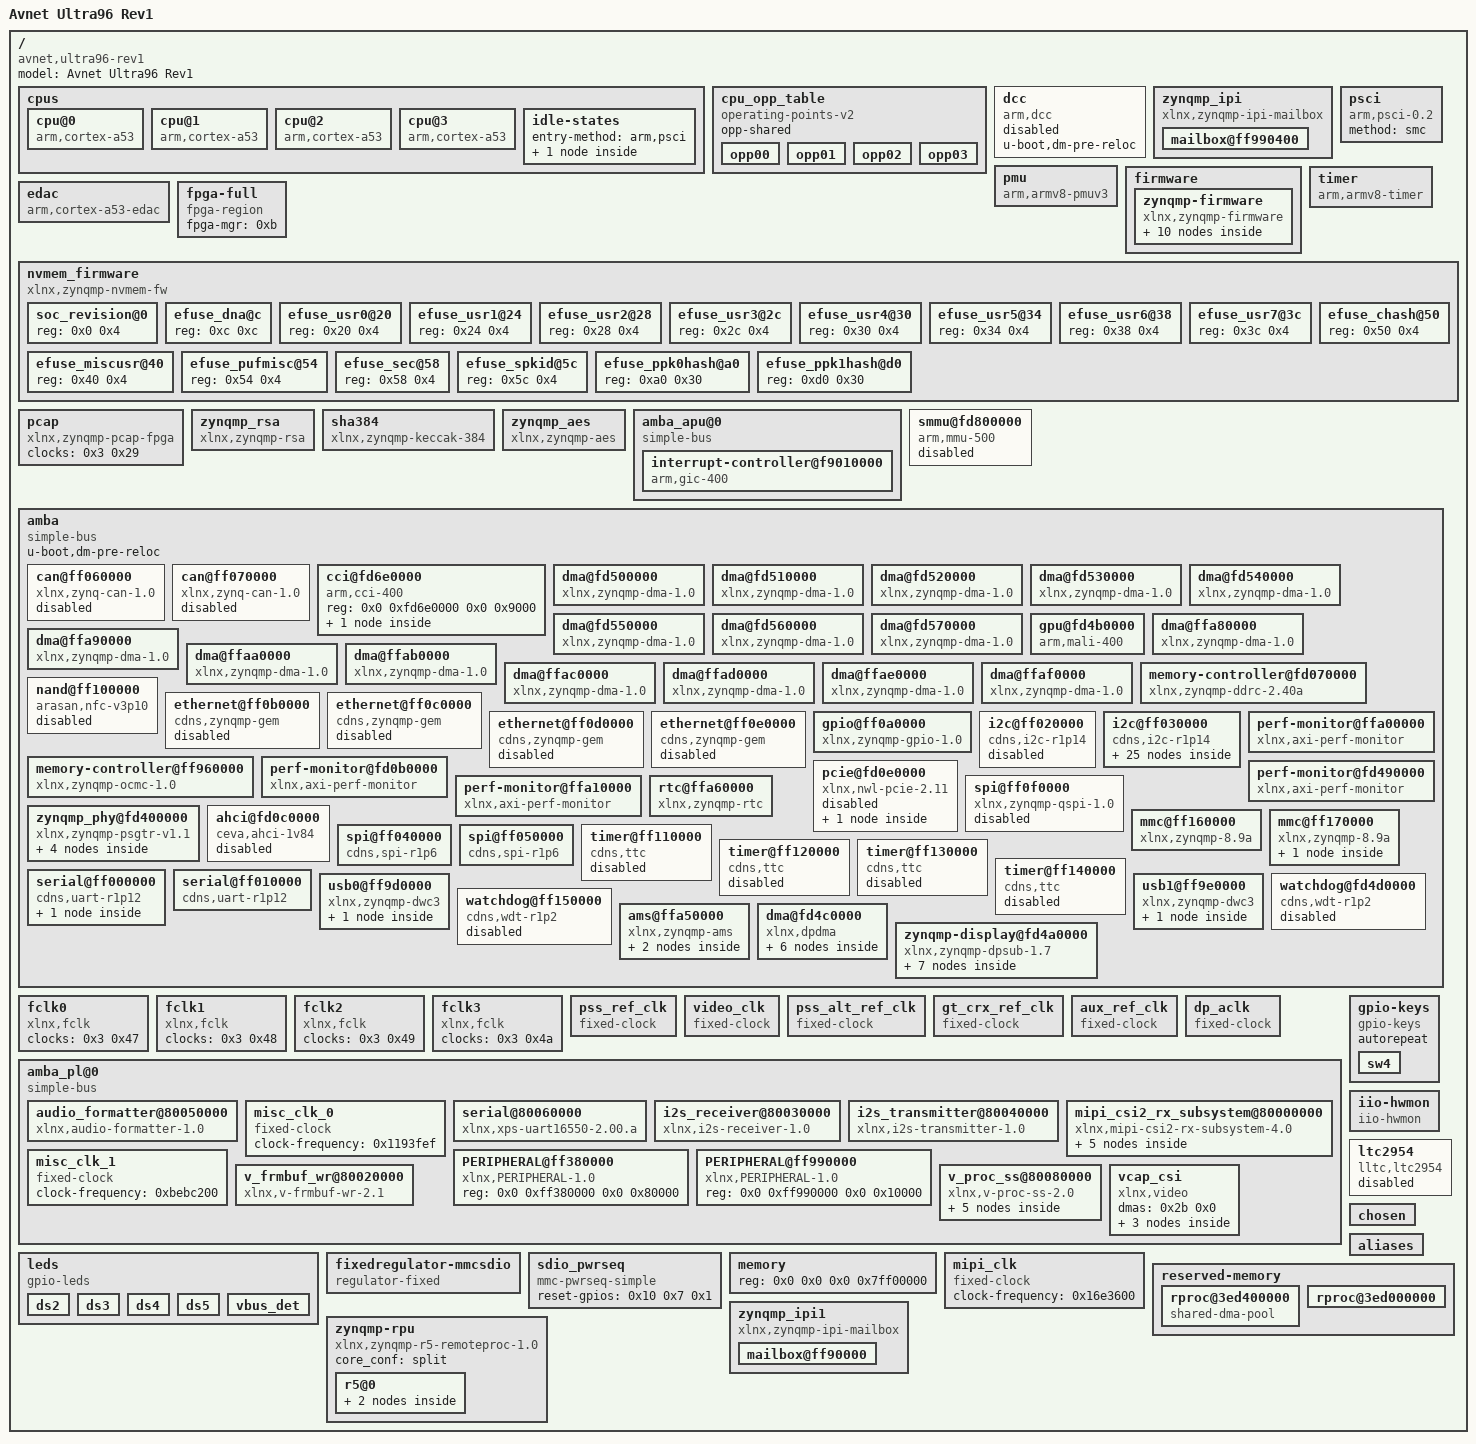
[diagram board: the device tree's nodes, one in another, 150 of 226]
/dts-v1/;

/ {
	compatible = "avnet,ultra96-rev1", "avnet,ultra96", "xlnx,zynqmp-zcu100-revC", "xlnx,zynqmp-zcu100", "xlnx,zynqmp";
	#address-cells = <0x2>;
	#size-cells = <0x2>;
	model = "Avnet Ultra96 Rev1";

	cpus {
		#address-cells = <0x1>;
		#size-cells = <0x0>;

		cpu@0 {
			compatible = "arm,cortex-a53", "arm,armv8";
			device_type = "cpu";
			enable-method = "psci";
			operating-points-v2 = <0x1>;
			reg = <0x0>;
			cpu-idle-states = <0x2>;
			clocks = <0x3 0xa>;
		};

		cpu@1 {
			compatible = "arm,cortex-a53", "arm,armv8";
			device_type = "cpu";
			enable-method = "psci";
			reg = <0x1>;
			operating-points-v2 = <0x1>;
			cpu-idle-states = <0x2>;
		};

		cpu@2 {
			compatible = "arm,cortex-a53", "arm,armv8";
			device_type = "cpu";
			enable-method = "psci";
			reg = <0x2>;
			operating-points-v2 = <0x1>;
			cpu-idle-states = <0x2>;
		};

		cpu@3 {
			compatible = "arm,cortex-a53", "arm,armv8";
			device_type = "cpu";
			enable-method = "psci";
			reg = <0x3>;
			operating-points-v2 = <0x1>;
			cpu-idle-states = <0x2>;
		};

		idle-states {
			entry-method = "arm,psci";

			cpu-sleep-0 {
				compatible = "arm,idle-state";
				arm,psci-suspend-param = <0x40000000>;
				local-timer-stop;
				entry-latency-us = <0x12c>;
				exit-latency-us = <0x258>;
				min-residency-us = <0x2710>;
				phandle = <0x2>;
			};
		};
	};

	cpu_opp_table {
		compatible = "operating-points-v2";
		opp-shared;
		phandle = <0x1>;

		opp00 {
			opp-hz = <0x0 0x47868bf4>;
			opp-microvolt = <0xf4240>;
			clock-latency-ns = <0x7a120>;
		};

		opp01 {
			opp-hz = <0x0 0x23c345fa>;
			opp-microvolt = <0xf4240>;
			clock-latency-ns = <0x7a120>;
		};

		opp02 {
			opp-hz = <0x0 0x17d783fc>;
			opp-microvolt = <0xf4240>;
			clock-latency-ns = <0x7a120>;
		};

		opp03 {
			opp-hz = <0x0 0x11e1a2fd>;
			opp-microvolt = <0xf4240>;
			clock-latency-ns = <0x7a120>;
		};
	};

	dcc {
		compatible = "arm,dcc";
		status = "disabled";
		u-boot,dm-pre-reloc;
	};

	zynqmp_ipi {
		compatible = "xlnx,zynqmp-ipi-mailbox";
		interrupt-parent = <0x4>;
		interrupts = <0x0 0x23 0x4>;
		xlnx,ipi-id = <0x0>;
		#address-cells = <0x2>;
		#size-cells = <0x2>;
		ranges;

		mailbox@ff990400 {
			reg = <0x0 0xff9905c0 0x0 0x20 0x0 0xff9905e0 0x0 0x20 0x0 0xff990e80 0x0 0x20 0x0 0xff990ea0 0x0 0x20>;
			reg-names = "local_request_region", "local_response_region", "remote_request_region", "remote_response_region";
			#mbox-cells = <0x1>;
			xlnx,ipi-id = <0x4>;
			phandle = <0x5>;
		};
	};

	pmu {
		compatible = "arm,armv8-pmuv3";
		interrupt-parent = <0x4>;
		interrupts = <0x0 0x8f 0x4 0x0 0x90 0x4 0x0 0x91 0x4 0x0 0x92 0x4>;
	};

	psci {
		compatible = "arm,psci-0.2";
		method = "smc";
	};

	firmware {

		zynqmp-firmware {
			compatible = "xlnx,zynqmp-firmware";
			u-boot,dm-pre-reloc;
			method = "smc";
			#power-domain-cells = <0x1>;
			phandle = <0xc>;

			zynqmp-power {
				compatible = "xlnx,zynqmp-power";
				interrupt-parent = <0x4>;
				interrupts = <0x0 0x23 0x4>;
				mboxes = <0x5 0x0 0x5 0x1>;
				mbox-names = "tx", "rx";
			};

			reset-controller {
				compatible = "xlnx,zynqmp-reset";
				#reset-cells = <0x1>;
				phandle = <0x16>;
			};

			pinctrl {
				compatible = "xlnx,zynqmp-pinctrl";
				status = "okay";

				i2c1-default {
					phandle = <0xe>;

					mux {
						groups = "i2c1_1_grp";
						function = "i2c1";
					};

					conf {
						groups = "i2c1_1_grp";
						bias-pull-up;
						slew-rate = <0x1>;
						io-standard = <0x1>;
					};
				};

				i2c1-gpio {
					phandle = <0xf>;

					mux {
						groups = "gpio0_4_grp", "gpio0_5_grp";
						function = "gpio0";
					};

					conf {
						groups = "gpio0_4_grp", "gpio0_5_grp";
						slew-rate = <0x1>;
						io-standard = <0x1>;
					};
				};
			};

			clock-controller {
				u-boot,dm-pre-reloc;
				#clock-cells = <0x1>;
				compatible = "xlnx,zynqmp-clk";
				clocks = <0x6 0x7 0x8 0x9 0xa>;
				clock-names = "pss_ref_clk", "video_clk", "pss_alt_ref_clk", "aux_ref_clk", "gt_crx_ref_clk";
				phandle = <0x3>;
			};
		};
	};

	timer {
		compatible = "arm,armv8-timer";
		interrupt-parent = <0x4>;
		interrupts = <0x1 0xd 0xf08 0x1 0xe 0xf08 0x1 0xb 0xf08 0x1 0xa 0xf08>;
	};

	edac {
		compatible = "arm,cortex-a53-edac";
	};

	fpga-full {
		compatible = "fpga-region";
		fpga-mgr = <0xb>;
		#address-cells = <0x2>;
		#size-cells = <0x2>;
	};

	nvmem_firmware {
		compatible = "xlnx,zynqmp-nvmem-fw";
		#address-cells = <0x1>;
		#size-cells = <0x1>;

		soc_revision@0 {
			reg = <0x0 0x4>;
			phandle = <0x15>;
		};

		efuse_dna@c {
			reg = <0xc 0xc>;
		};

		efuse_usr0@20 {
			reg = <0x20 0x4>;
		};

		efuse_usr1@24 {
			reg = <0x24 0x4>;
		};

		efuse_usr2@28 {
			reg = <0x28 0x4>;
		};

		efuse_usr3@2c {
			reg = <0x2c 0x4>;
		};

		efuse_usr4@30 {
			reg = <0x30 0x4>;
		};

		efuse_usr5@34 {
			reg = <0x34 0x4>;
		};

		efuse_usr6@38 {
			reg = <0x38 0x4>;
		};

		efuse_usr7@3c {
			reg = <0x3c 0x4>;
		};

		efuse_miscusr@40 {
			reg = <0x40 0x4>;
		};

		efuse_chash@50 {
			reg = <0x50 0x4>;
		};

		efuse_pufmisc@54 {
			reg = <0x54 0x4>;
		};

		efuse_sec@58 {
			reg = <0x58 0x4>;
		};

		efuse_spkid@5c {
			reg = <0x5c 0x4>;
		};

		efuse_ppk0hash@a0 {
			reg = <0xa0 0x30>;
		};

		efuse_ppk1hash@d0 {
			reg = <0xd0 0x30>;
		};
	};

	pcap {
		compatible = "xlnx,zynqmp-pcap-fpga";
		clock-names = "ref_clk";
		clocks = <0x3 0x29>;
		phandle = <0xb>;
	};

	zynqmp_rsa {
		compatible = "xlnx,zynqmp-rsa";
	};

	sha384 {
		compatible = "xlnx,zynqmp-keccak-384";
	};

	zynqmp_aes {
		compatible = "xlnx,zynqmp-aes";
	};

	amba_apu@0 {
		compatible = "simple-bus";
		#address-cells = <0x2>;
		#size-cells = <0x1>;
		ranges = <0x0 0x0 0x0 0x0 0xffffffff>;

		interrupt-controller@f9010000 {
			compatible = "arm,gic-400", "arm,cortex-a15-gic";
			#interrupt-cells = <0x3>;
			reg = <0x0 0xf9010000 0x10000 0x0 0xf9020000 0x20000 0x0 0xf9040000 0x20000 0x0 0xf9060000 0x20000>;
			interrupt-controller;
			interrupt-parent = <0x4>;
			interrupts = <0x1 0x9 0xf04>;
			num_cpus = <0x2>;
			num_interrupts = <0x60>;
			phandle = <0x4>;
		};
	};

	smmu@fd800000 {
		compatible = "arm,mmu-500";
		reg = <0x0 0xfd800000 0x0 0x20000>;
		#iommu-cells = <0x1>;
		status = "disabled";
		#global-interrupts = <0x1>;
		interrupt-parent = <0x4>;
		interrupts = <0x0 0x9b 0x4 0x0 0x9b 0x4 0x0 0x9b 0x4 0x0 0x9b 0x4 0x0 0x9b 0x4 0x0 0x9b 0x4 0x0 0x9b 0x4 0x0 0x9b 0x4 0x0 0x9b 0x4 0x0 0x9b 0x4 0x0 0x9b 0x4 0x0 0x9b 0x4 0x0 0x9b 0x4 0x0 0x9b 0x4 0x0 0x9b 0x4 0x0 0x9b 0x4 0x0 0x9b 0x4>;
		phandle = <0xd>;
	};

	amba {
		compatible = "simple-bus";
		u-boot,dm-pre-reloc;
		#address-cells = <0x2>;
		#size-cells = <0x2>;
		ranges;

		can@ff060000 {
			compatible = "xlnx,zynq-can-1.0";
			status = "disabled";
			clock-names = "can_clk", "pclk";
			reg = <0x0 0xff060000 0x0 0x1000>;
			interrupts = <0x0 0x17 0x4>;
			interrupt-parent = <0x4>;
			tx-fifo-depth = <0x40>;
			rx-fifo-depth = <0x40>;
			power-domains = <0xc 0x2f>;
			clocks = <0x3 0x3f 0x3 0x1f>;
		};

		can@ff070000 {
			compatible = "xlnx,zynq-can-1.0";
			status = "disabled";
			clock-names = "can_clk", "pclk";
			reg = <0x0 0xff070000 0x0 0x1000>;
			interrupts = <0x0 0x18 0x4>;
			interrupt-parent = <0x4>;
			tx-fifo-depth = <0x40>;
			rx-fifo-depth = <0x40>;
			power-domains = <0xc 0x30>;
			clocks = <0x3 0x40 0x3 0x1f>;
		};

		cci@fd6e0000 {
			compatible = "arm,cci-400";
			reg = <0x0 0xfd6e0000 0x0 0x9000>;
			ranges = <0x0 0x0 0xfd6e0000 0x10000>;
			#address-cells = <0x1>;
			#size-cells = <0x1>;

			pmu@9000 {
				compatible = "arm,cci-400-pmu,r1";
				reg = <0x9000 0x5000>;
				interrupt-parent = <0x4>;
				interrupts = <0x0 0x7b 0x4 0x0 0x7b 0x4 0x0 0x7b 0x4 0x0 0x7b 0x4 0x0 0x7b 0x4>;
			};
		};

		dma@fd500000 {
			status = "okay";
			compatible = "xlnx,zynqmp-dma-1.0";
			reg = <0x0 0xfd500000 0x0 0x1000>;
			interrupt-parent = <0x4>;
			interrupts = <0x0 0x7c 0x4>;
			clock-names = "clk_main", "clk_apb";
			xlnx,bus-width = <0x80>;
			#stream-id-cells = <0x1>;
			iommus = <0xd 0x14e8>;
			power-domains = <0xc 0x2a>;
			clocks = <0x3 0x13 0x3 0x1f>;
		};

		dma@fd510000 {
			status = "okay";
			compatible = "xlnx,zynqmp-dma-1.0";
			reg = <0x0 0xfd510000 0x0 0x1000>;
			interrupt-parent = <0x4>;
			interrupts = <0x0 0x7d 0x4>;
			clock-names = "clk_main", "clk_apb";
			xlnx,bus-width = <0x80>;
			#stream-id-cells = <0x1>;
			iommus = <0xd 0x14e9>;
			power-domains = <0xc 0x2a>;
			clocks = <0x3 0x13 0x3 0x1f>;
		};

		dma@fd520000 {
			status = "okay";
			compatible = "xlnx,zynqmp-dma-1.0";
			reg = <0x0 0xfd520000 0x0 0x1000>;
			interrupt-parent = <0x4>;
			interrupts = <0x0 0x7e 0x4>;
			clock-names = "clk_main", "clk_apb";
			xlnx,bus-width = <0x80>;
			#stream-id-cells = <0x1>;
			iommus = <0xd 0x14ea>;
			power-domains = <0xc 0x2a>;
			clocks = <0x3 0x13 0x3 0x1f>;
		};

		dma@fd530000 {
			status = "okay";
			compatible = "xlnx,zynqmp-dma-1.0";
			reg = <0x0 0xfd530000 0x0 0x1000>;
			interrupt-parent = <0x4>;
			interrupts = <0x0 0x7f 0x4>;
			clock-names = "clk_main", "clk_apb";
			xlnx,bus-width = <0x80>;
			#stream-id-cells = <0x1>;
			iommus = <0xd 0x14eb>;
			power-domains = <0xc 0x2a>;
			clocks = <0x3 0x13 0x3 0x1f>;
		};

		dma@fd540000 {
			status = "okay";
			compatible = "xlnx,zynqmp-dma-1.0";
			reg = <0x0 0xfd540000 0x0 0x1000>;
			interrupt-parent = <0x4>;
			interrupts = <0x0 0x80 0x4>;
			clock-names = "clk_main", "clk_apb";
			xlnx,bus-width = <0x80>;
			#stream-id-cells = <0x1>;
			iommus = <0xd 0x14ec>;
			power-domains = <0xc 0x2a>;
			clocks = <0x3 0x13 0x3 0x1f>;
		};

		dma@fd550000 {
			status = "okay";
			compatible = "xlnx,zynqmp-dma-1.0";
			reg = <0x0 0xfd550000 0x0 0x1000>;
			interrupt-parent = <0x4>;
			interrupts = <0x0 0x81 0x4>;
			clock-names = "clk_main", "clk_apb";
			xlnx,bus-width = <0x80>;
			#stream-id-cells = <0x1>;
			iommus = <0xd 0x14ed>;
			power-domains = <0xc 0x2a>;
			clocks = <0x3 0x13 0x3 0x1f>;
		};

		dma@fd560000 {
			status = "okay";
			compatible = "xlnx,zynqmp-dma-1.0";
			reg = <0x0 0xfd560000 0x0 0x1000>;
			interrupt-parent = <0x4>;
			interrupts = <0x0 0x82 0x4>;
			clock-names = "clk_main", "clk_apb";
			xlnx,bus-width = <0x80>;
			#stream-id-cells = <0x1>;
			iommus = <0xd 0x14ee>;
			power-domains = <0xc 0x2a>;
			clocks = <0x3 0x13 0x3 0x1f>;
		};

		dma@fd570000 {
			status = "okay";
			compatible = "xlnx,zynqmp-dma-1.0";
			reg = <0x0 0xfd570000 0x0 0x1000>;
			interrupt-parent = <0x4>;
			interrupts = <0x0 0x83 0x4>;
			clock-names = "clk_main", "clk_apb";
			xlnx,bus-width = <0x80>;
			#stream-id-cells = <0x1>;
			iommus = <0xd 0x14ef>;
			power-domains = <0xc 0x2a>;
			clocks = <0x3 0x13 0x3 0x1f>;
		};

		gpu@fd4b0000 {
			status = "okay";
			compatible = "arm,mali-400", "arm,mali-utgard";
			reg = <0x0 0xfd4b0000 0x0 0x10000>;
			interrupt-parent = <0x4>;
			interrupts = <0x0 0x84 0x4 0x0 0x84 0x4 0x0 0x84 0x4 0x0 0x84 0x4 0x0 0x84 0x4 0x0 0x84 0x4>;
			interrupt-names = "IRQGP", "IRQGPMMU", "IRQPP0", "IRQPPMMU0", "IRQPP1", "IRQPPMMU1";
			clock-names = "gpu", "gpu_pp0", "gpu_pp1";
			power-domains = <0xc 0x3a>;
			clocks = <0x3 0x18 0x3 0x19 0x3 0x1a>;
			xlnx,tz-nonsecure = <0x1>;
		};

		dma@ffa80000 {
			status = "okay";
			compatible = "xlnx,zynqmp-dma-1.0";
			reg = <0x0 0xffa80000 0x0 0x1000>;
			interrupt-parent = <0x4>;
			interrupts = <0x0 0x4d 0x4>;
			clock-names = "clk_main", "clk_apb";
			xlnx,bus-width = <0x40>;
			#stream-id-cells = <0x1>;
			power-domains = <0xc 0x2b>;
			clocks = <0x3 0x44 0x3 0x1f>;
		};

		dma@ffa90000 {
			status = "okay";
			compatible = "xlnx,zynqmp-dma-1.0";
			reg = <0x0 0xffa90000 0x0 0x1000>;
			interrupt-parent = <0x4>;
			interrupts = <0x0 0x4e 0x4>;
			clock-names = "clk_main", "clk_apb";
			xlnx,bus-width = <0x40>;
			#stream-id-cells = <0x1>;
			power-domains = <0xc 0x2b>;
			clocks = <0x3 0x44 0x3 0x1f>;
		};

		dma@ffaa0000 {
			status = "okay";
			compatible = "xlnx,zynqmp-dma-1.0";
			reg = <0x0 0xffaa0000 0x0 0x1000>;
			interrupt-parent = <0x4>;
			interrupts = <0x0 0x4f 0x4>;
			clock-names = "clk_main", "clk_apb";
			xlnx,bus-width = <0x40>;
			#stream-id-cells = <0x1>;
			power-domains = <0xc 0x2b>;
			clocks = <0x3 0x44 0x3 0x1f>;
		};

		dma@ffab0000 {
			status = "okay";
			compatible = "xlnx,zynqmp-dma-1.0";
			reg = <0x0 0xffab0000 0x0 0x1000>;
			interrupt-parent = <0x4>;
			interrupts = <0x0 0x50 0x4>;
			clock-names = "clk_main", "clk_apb";
			xlnx,bus-width = <0x40>;
			#stream-id-cells = <0x1>;
			power-domains = <0xc 0x2b>;
			clocks = <0x3 0x44 0x3 0x1f>;
		};

		dma@ffac0000 {
			status = "okay";
			compatible = "xlnx,zynqmp-dma-1.0";
			reg = <0x0 0xffac0000 0x0 0x1000>;
			interrupt-parent = <0x4>;
			interrupts = <0x0 0x51 0x4>;
			clock-names = "clk_main", "clk_apb";
			xlnx,bus-width = <0x40>;
			#stream-id-cells = <0x1>;
			power-domains = <0xc 0x2b>;
			clocks = <0x3 0x44 0x3 0x1f>;
		};

		dma@ffad0000 {
			status = "okay";
			compatible = "xlnx,zynqmp-dma-1.0";
			reg = <0x0 0xffad0000 0x0 0x1000>;
			interrupt-parent = <0x4>;
			interrupts = <0x0 0x52 0x4>;
			clock-names = "clk_main", "clk_apb";
			xlnx,bus-width = <0x40>;
			#stream-id-cells = <0x1>;
			power-domains = <0xc 0x2b>;
			clocks = <0x3 0x44 0x3 0x1f>;
		};

		dma@ffae0000 {
			status = "okay";
			compatible = "xlnx,zynqmp-dma-1.0";
			reg = <0x0 0xffae0000 0x0 0x1000>;
			interrupt-parent = <0x4>;
			interrupts = <0x0 0x53 0x4>;
			clock-names = "clk_main", "clk_apb";
			xlnx,bus-width = <0x40>;
			#stream-id-cells = <0x1>;
			power-domains = <0xc 0x2b>;
			clocks = <0x3 0x44 0x3 0x1f>;
		};

		dma@ffaf0000 {
			status = "okay";
			compatible = "xlnx,zynqmp-dma-1.0";
			reg = <0x0 0xffaf0000 0x0 0x1000>;
			interrupt-parent = <0x4>;
			interrupts = <0x0 0x54 0x4>;
			clock-names = "clk_main", "clk_apb";
			xlnx,bus-width = <0x40>;
			#stream-id-cells = <0x1>;
			power-domains = <0xc 0x2b>;
			clocks = <0x3 0x44 0x3 0x1f>;
		};

		memory-controller@fd070000 {
			compatible = "xlnx,zynqmp-ddrc-2.40a";
			reg = <0x0 0xfd070000 0x0 0x30000>;
			interrupt-parent = <0x4>;
			interrupts = <0x0 0x70 0x4>;
		};

		nand@ff100000 {
			compatible = "arasan,nfc-v3p10";
			status = "disabled";
			reg = <0x0 0xff100000 0x0 0x1000>;
			clock-names = "clk_sys", "clk_flash";
			interrupt-parent = <0x4>;
			interrupts = <0x0 0xe 0x4>;
			#address-cells = <0x1>;
			#size-cells = <0x0>;
			#stream-id-cells = <0x1>;
			iommus = <0xd 0x872>;
			power-domains = <0xc 0x2c>;
			clocks = <0x3 0x3c 0x3 0x1f>;
		};

		ethernet@ff0b0000 {
			compatible = "cdns,zynqmp-gem", "cdns,gem";
			status = "disabled";
			interrupt-parent = <0x4>;
			interrupts = <0x0 0x39 0x4 0x0 0x39 0x4>;
			reg = <0x0 0xff0b0000 0x0 0x1000>;
			clock-names = "pclk", "hclk", "tx_clk", "rx_clk", "tsu_clk";
			#address-cells = <0x1>;
			#size-cells = <0x0>;
			#stream-id-cells = <0x1>;
			iommus = <0xd 0x874>;
			power-domains = <0xc 0x1d>;
			clocks = <0x3 0x1f 0x3 0x68 0x3 0x2d 0x3 0x31 0x3 0x2c>;
		};

		ethernet@ff0c0000 {
			compatible = "cdns,zynqmp-gem", "cdns,gem";
			status = "disabled";
			interrupt-parent = <0x4>;
			interrupts = <0x0 0x3b 0x4 0x0 0x3b 0x4>;
			reg = <0x0 0xff0c0000 0x0 0x1000>;
			clock-names = "pclk", "hclk", "tx_clk", "rx_clk", "tsu_clk";
			#address-cells = <0x1>;
			#size-cells = <0x0>;
			#stream-id-cells = <0x1>;
			iommus = <0xd 0x875>;
			power-domains = <0xc 0x1e>;
			clocks = <0x3 0x1f 0x3 0x69 0x3 0x2e 0x3 0x32 0x3 0x2c>;
		};

		ethernet@ff0d0000 {
			compatible = "cdns,zynqmp-gem", "cdns,gem";
			status = "disabled";
			interrupt-parent = <0x4>;
			interrupts = <0x0 0x3d 0x4 0x0 0x3d 0x4>;
			reg = <0x0 0xff0d0000 0x0 0x1000>;
			clock-names = "pclk", "hclk", "tx_clk", "rx_clk", "tsu_clk";
			#address-cells = <0x1>;
			#size-cells = <0x0>;
			#stream-id-cells = <0x1>;
			iommus = <0xd 0x876>;
			power-domains = <0xc 0x1f>;
			clocks = <0x3 0x1f 0x3 0x6a 0x3 0x2f 0x3 0x33 0x3 0x2c>;
		};

		ethernet@ff0e0000 {
			compatible = "cdns,zynqmp-gem", "cdns,gem";
			status = "disabled";
			interrupt-parent = <0x4>;
			interrupts = <0x0 0x3f 0x4 0x0 0x3f 0x4>;
			reg = <0x0 0xff0e0000 0x0 0x1000>;
			clock-names = "pclk", "hclk", "tx_clk", "rx_clk", "tsu_clk";
			#address-cells = <0x1>;
			#size-cells = <0x0>;
			#stream-id-cells = <0x1>;
			iommus = <0xd 0x877>;
			power-domains = <0xc 0x20>;
			clocks = <0x3 0x1f 0x3 0x6b 0x3 0x30 0x3 0x34 0x3 0x2c>;
		};

		gpio@ff0a0000 {
			compatible = "xlnx,zynqmp-gpio-1.0";
			status = "okay";
			#gpio-cells = <0x2>;
			interrupt-parent = <0x4>;
			interrupts = <0x0 0x10 0x4>;
			interrupt-controller;
			#interrupt-cells = <0x2>;
			reg = <0x0 0xff0a0000 0x0 0x1000>;
			gpio-controller;
			power-domains = <0xc 0x2e>;
			clocks = <0x3 0x1f>;
			emio-gpio-width = <0x20>;
			gpio-mask-high = <0x0>;
			gpio-mask-low = <0x5600>;
			gpio-line-names = "UART1_TX", "UART1_RX", "UART0_RX", "UART0_TX", "I2C1_SCL", "I2C1_SDA", "SPI1_SCLK", "WLAN_EN", "BT_EN", "SPI1_CS", "SPI1_MISO", "SPI1_MOSI", "I2C_MUX_RESET", "SD0_DAT0", "SD0_DAT1", "SD0_DAT2", "SD0_DAT3", "PS_LED3", "PS_LED2", "PS_LED1", "PS_LED0", "SD0_CMD", "SD0_CLK", "GPIO_PB", "SD0_DETECT", "VBUS_DET", "POWER_INT", "DP_AUX", "DP_HPD", "DP_OE", "DP_AUX_IN", "INA226_ALERT", "PS_FP_PWR_EN", "PL_PWR_EN", "POWER_KILL", "", "GPIO-A", "GPIO-B", "SPI0_SCLK", "GPIO-C", "GPIO-D", "SPI0_CS", "SPI0_MISO", "SPI_MOSI", "GPIO-E", "GPIO-F", "SD1_D0", "SD1_D1", "SD1_D2", "SD1_D3", "SD1_CMD", "SD1_CLK", "USB0_CLK", "USB0_DIR", "USB0_DATA2", "USB0_NXT", "USB0_DATA0", "USB0_DATA1", "USB0_STP", "USB0_DATA3", "USB0_DATA4", "USB0_DATA5", "USB0_DATA6", "USB0_DATA7", "USB1_CLK", "USB1_DIR", "USB1_DATA2", "USB1_NXT", "USB1_DATA0", "USB1_DATA1", "USB1_STP", "USB1_DATA3", "USB1_DATA4", "USB1_DATA5", "USB1_DATA6", "USB_DATA7", "WLAN_IRQ", "PMIC_IRQ", "", "", "", "", "", "", "", "", "", "", "", "", "", "", "", "", "", "", "", "", "", "", "", "", "", "", "", "", "", "", "", "", "", "", "", "", "", "", "", "", "", "", "", "", "", "", "", "", "", "", "", "", "", "", "", "", "", "", "", "", "", "", "", "", "", "", "", "", "", "", "", "", "", "", "", "", "", "", "", "", "", "", "", "", "", "", "", "", "", "", "", "", "", "", "", "";
			phandle = <0x10>;
		};

		i2c@ff020000 {
			compatible = "cdns,i2c-r1p14", "cdns,i2c-r1p10";
			status = "disabled";
			interrupt-parent = <0x4>;
			interrupts = <0x0 0x11 0x4>;
			reg = <0x0 0xff020000 0x0 0x1000>;
			#address-cells = <0x1>;
			#size-cells = <0x0>;
			power-domains = <0xc 0x25>;
			clocks = <0x3 0x3d>;
		};

		i2c@ff030000 {
			compatible = "cdns,i2c-r1p14", "cdns,i2c-r1p10";
			status = "okay";
			interrupt-parent = <0x4>;
			interrupts = <0x0 0x12 0x4>;
			reg = <0x0 0xff030000 0x0 0x1000>;
			#address-cells = <0x1>;
			#size-cells = <0x0>;
			power-domains = <0xc 0x26>;
			clocks = <0x3 0x3e>;
			clock-frequency = <0x186a0>;
			pinctrl-names = "default", "gpio";
			pinctrl-0 = <0xe>;
			pinctrl-1 = <0xf>;
			scl-gpios = <0x10 0x4 0x0>;
			sda-gpios = <0x10 0x5 0x0>;

			i2c-mux@75 {
				compatible = "nxp,pca9548";
				#address-cells = <0x1>;
				#size-cells = <0x0>;
				reg = <0x75>;

				i2c@0 {
					#address-cells = <0x1>;
					#size-cells = <0x0>;
					reg = <0x0>;
					label = "LS-I2C0";
					/*
					vision0: camera-sensor@6a {
						compatible = "sensing,vision";
						reg = <0x6a>;
//						sensor-reg = <0x51 0x52 0x53 0x54>;
//						isp-reg = <0x61 0x62 0x63 0x64>;
						// one camera
						sensor-reg = <0x51>;
						isp-reg = <0x61>;

						port {
							vision_ep0: endpoint {
								clock-lanes = <1>;
								data-lanes = <0 2 3 4>;
							//	remote-endpoint = <&csiphy0_ep>;
								remote-endpoint = <0x12>;
							};
						};
					};
					*/
					gmsl-deserializer@6a {
						compatible = "maxim,max9286";
						reg = <0x6a>;
						ports {
							#address-cells = <1>;
							#size-cells = <0>;
							port@0 {
								reg = <0>;
								max9286_in0: endpoint {
									remote-endpoint = <&vision_ep0>;
								};
							};
							port@1 {
								reg = <1>;
							};
							port@2 {
								reg = <2>;
							};
							port@3 {
								reg = <3>;
							};
							port@4 {
								reg = <4>;
								max9286_out: endpoint {
									data-lanes = <1 2 3 4>;
									remote-endpoint = <0x12>;
								};
							};
						};
						i2c-mux {
							#address-cells = <1>;
							#size-cells = <0>;
							i2c@0 {
								#address-cells = <1>;
								#size-cells = <0>;
								reg = <0>;
								/*
								camera@51 {
								  reg = <0x51>;
								  port {
								    rdacm20_out0: endpoint {
								      remote-endpoint = <&max9286_in0>;
								    };
								  };
								};
								*/
								vision0: camera-sensor@6a {
									compatible = "sensing,vision";
									reg = <0x6a>;
//									sensor-reg = <0x51 0x52 0x53 0x54>;
//									isp-reg = <0x61 0x62 0x63 0x64>;
									// one camera
									sensor-reg = <0x51>;
									isp-reg = <0x61>;
									port {
										vision_ep0: endpoint {
											clock-lanes = <1>;
											data-lanes = <0 2 3 4>;
										//	remote-endpoint = <&csiphy0_ep>;
										//	remote-endpoint = <0x12>;
											remote-endpoint = <&max9286_in0>;
										};
									};
								};
							};
						};
					};
				};

				i2c@1 {
					#address-cells = <0x1>;
					#size-cells = <0x0>;
					reg = <0x1>;
					label = "LS-I2C1";
					/*
					vision1: camera-sensor@6a {
						compatible = "sensing,vision";
						reg = <0x6a>;
//						sensor-reg = <0x51 0x52 0x53 0x54>;
//						isp-reg = <0x61 0x62 0x63 0x64>;
						// one camera
						sensor-reg = <0x51>;
						isp-reg = <0x61>;

						port {
							vision_ep1: endpoint {
								clock-lanes = <1>;
								data-lanes = <0 2 3 4>;
							//	remote-endpoint = <&csiphy0_ep>;
							//	remote-endpoint = <0x12>;
							};
						};
					};
					*/
				};

				i2c@2 {
					#address-cells = <0x1>;
					#size-cells = <0x0>;
					reg = <0x2>;
					label = "HS-I2C2";

					/*
					camera@3c {
						compatible = "ovti,ov5640";
						reg = <0x3c>;
						clock-names = "xclk";
						clocks = <0x11>;
						powerdown-gpios = <0x10 0x51 0x0>;
						reset-gpios = <0x10 0x50 0x1>;

						port {

							endpoint {
								remote-endpoint = <0x12>;
								clock-lanes = <0x0>;
								data-lanes = <0x1 0x2>;
								phandle = <0x28>;
							};
						};
					};
					*/
				};

				i2c@3 {
					#address-cells = <0x1>;
					#size-cells = <0x0>;
					reg = <0x3>;
					label = "HS-I2C3";
				};

				i2c@4 {
					#address-cells = <0x1>;
					#size-cells = <0x0>;
					reg = <0x4>;

					pmic@5e {
						compatible = "ti,tps65086";
						reg = <0x5e>;
						interrupt-parent = <0x10>;
						interrupts = <0x4d 0x1>;
						#gpio-cells = <0x2>;
						gpio-controller;
					};
				};

				i2c@5 {
					#address-cells = <0x1>;
					#size-cells = <0x0>;
					reg = <0x5>;

					ina226@40 {
						compatible = "ti,ina226";
						reg = <0x40>;
						shunt-resistor = <0x2710>;
					};
				};

				i2c@6 {
					#address-cells = <0x1>;
					#size-cells = <0x0>;
					reg = <0x6>;
				};

				i2c@7 {
					#address-cells = <0x1>;
					#size-cells = <0x0>;
					reg = <0x7>;
				};
			};
		};

		memory-controller@ff960000 {
			compatible = "xlnx,zynqmp-ocmc-1.0";
			reg = <0x0 0xff960000 0x0 0x1000>;
			interrupt-parent = <0x4>;
			interrupts = <0x0 0xa 0x4>;
		};

		perf-monitor@ffa00000 {
			compatible = "xlnx,axi-perf-monitor";
			reg = <0x0 0xffa00000 0x0 0x10000>;
			interrupts = <0x0 0x19 0x4>;
			interrupt-parent = <0x4>;
			xlnx,enable-profile = <0x0>;
			xlnx,enable-trace = <0x0>;
			xlnx,num-monitor-slots = <0x1>;
			xlnx,enable-event-count = <0x1>;
			xlnx,enable-event-log = <0x1>;
			xlnx,have-sampled-metric-cnt = <0x1>;
			xlnx,num-of-counters = <0x8>;
			xlnx,metric-count-width = <0x20>;
			xlnx,metrics-sample-count-width = <0x20>;
			xlnx,global-count-width = <0x20>;
			xlnx,metric-count-scale = <0x1>;
			clocks = <0x3 0x1f>;
		};

		perf-monitor@fd0b0000 {
			compatible = "xlnx,axi-perf-monitor";
			reg = <0x0 0xfd0b0000 0x0 0x10000>;
			interrupts = <0x0 0x7b 0x4>;
			interrupt-parent = <0x4>;
			xlnx,enable-profile = <0x0>;
			xlnx,enable-trace = <0x0>;
			xlnx,num-monitor-slots = <0x6>;
			xlnx,enable-event-count = <0x1>;
			xlnx,enable-event-log = <0x0>;
			xlnx,have-sampled-metric-cnt = <0x1>;
			xlnx,num-of-counters = <0xa>;
			xlnx,metric-count-width = <0x20>;
			xlnx,metrics-sample-count-width = <0x20>;
			xlnx,global-count-width = <0x20>;
			xlnx,metric-count-scale = <0x1>;
			clocks = <0x3 0x1c>;
		};

		perf-monitor@fd490000 {
			compatible = "xlnx,axi-perf-monitor";
			reg = <0x0 0xfd490000 0x0 0x10000>;
			interrupts = <0x0 0x7b 0x4>;
			interrupt-parent = <0x4>;
			xlnx,enable-profile = <0x0>;
			xlnx,enable-trace = <0x0>;
			xlnx,num-monitor-slots = <0x1>;
			xlnx,enable-event-count = <0x1>;
			xlnx,enable-event-log = <0x0>;
			xlnx,have-sampled-metric-cnt = <0x1>;
			xlnx,num-of-counters = <0x8>;
			xlnx,metric-count-width = <0x20>;
			xlnx,metrics-sample-count-width = <0x20>;
			xlnx,global-count-width = <0x20>;
			xlnx,metric-count-scale = <0x1>;
			clocks = <0x3 0x1c>;
		};

		perf-monitor@ffa10000 {
			compatible = "xlnx,axi-perf-monitor";
			reg = <0x0 0xffa10000 0x0 0x10000>;
			interrupts = <0x0 0x19 0x4>;
			interrupt-parent = <0x4>;
			xlnx,enable-profile = <0x0>;
			xlnx,enable-trace = <0x0>;
			xlnx,num-monitor-slots = <0x1>;
			xlnx,enable-event-count = <0x1>;
			xlnx,enable-event-log = <0x1>;
			xlnx,have-sampled-metric-cnt = <0x1>;
			xlnx,num-of-counters = <0x8>;
			xlnx,metric-count-width = <0x20>;
			xlnx,metrics-sample-count-width = <0x20>;
			xlnx,global-count-width = <0x20>;
			xlnx,metric-count-scale = <0x1>;
			clocks = <0x3 0x1f>;
		};

		pcie@fd0e0000 {
			compatible = "xlnx,nwl-pcie-2.11";
			status = "disabled";
			#address-cells = <0x3>;
			#size-cells = <0x2>;
			#interrupt-cells = <0x1>;
			msi-controller;
			device_type = "pci";
			interrupt-parent = <0x4>;
			interrupts = <0x0 0x76 0x4 0x0 0x75 0x4 0x0 0x74 0x4 0x0 0x73 0x4 0x0 0x72 0x4>;
			interrupt-names = "misc", "dummy", "intx", "msi1", "msi0";
			msi-parent = <0x13>;
			reg = <0x0 0xfd0e0000 0x0 0x1000 0x0 0xfd480000 0x0 0x1000 0x80 0x0 0x0 0x1000000>;
			reg-names = "breg", "pcireg", "cfg";
			ranges = <0x2000000 0x0 0xe0000000 0x0 0xe0000000 0x0 0x10000000 0x43000000 0x6 0x0 0x6 0x0 0x2 0x0>;
			interrupt-map-mask = <0x0 0x0 0x0 0x7>;
			bus-range = <0x0 0xff>;
			interrupt-map = <0x0 0x0 0x0 0x1 0x14 0x1 0x0 0x0 0x0 0x2 0x14 0x2 0x0 0x0 0x0 0x3 0x14 0x3 0x0 0x0 0x0 0x4 0x14 0x4>;
			power-domains = <0xc 0x3b>;
			clocks = <0x3 0x17>;
			phandle = <0x13>;

			legacy-interrupt-controller {
				interrupt-controller;
				#address-cells = <0x0>;
				#interrupt-cells = <0x1>;
				phandle = <0x14>;
			};
		};

		spi@ff0f0000 {
			u-boot,dm-pre-reloc;
			compatible = "xlnx,zynqmp-qspi-1.0";
			status = "disabled";
			clock-names = "ref_clk", "pclk";
			interrupts = <0x0 0xf 0x4>;
			interrupt-parent = <0x4>;
			num-cs = <0x1>;
			reg = <0x0 0xff0f0000 0x0 0x1000 0x0 0xc0000000 0x0 0x8000000>;
			#address-cells = <0x1>;
			#size-cells = <0x0>;
			#stream-id-cells = <0x1>;
			iommus = <0xd 0x873>;
			power-domains = <0xc 0x2d>;
			clocks = <0x3 0x35 0x3 0x1f>;
		};

		rtc@ffa60000 {
			compatible = "xlnx,zynqmp-rtc";
			status = "okay";
			reg = <0x0 0xffa60000 0x0 0x100>;
			interrupt-parent = <0x4>;
			interrupts = <0x0 0x1a 0x4 0x0 0x1b 0x4>;
			interrupt-names = "alarm", "sec";
			calibration = <0x8000>;
		};

		zynqmp_phy@fd400000 {
			compatible = "xlnx,zynqmp-psgtr-v1.1";
			status = "okay";
			reg = <0x0 0xfd400000 0x0 0x40000 0x0 0xfd3d0000 0x0 0x1000>;
			reg-names = "serdes", "siou";
			nvmem-cells = <0x15>;
			nvmem-cell-names = "soc_revision";
			resets = <0x16 0x10 0x16 0x3b 0x16 0x3c 0x16 0x3d 0x16 0x3e 0x16 0x3f 0x16 0x40 0x16 0x3 0x16 0x1d 0x16 0x1e 0x16 0x1f 0x16 0x20>;
			reset-names = "sata_rst", "usb0_crst", "usb1_crst", "usb0_hibrst", "usb1_hibrst", "usb0_apbrst", "usb1_apbrst", "dp_rst", "gem0_rst", "gem1_rst", "gem2_rst", "gem3_rst";

			lane0 {
				#phy-cells = <0x4>;
				phandle = <0x1d>;
			};

			lane1 {
				#phy-cells = <0x4>;
				phandle = <0x1c>;
			};

			lane2 {
				#phy-cells = <0x4>;
				phandle = <0x19>;
			};

			lane3 {
				#phy-cells = <0x4>;
				phandle = <0x1a>;
			};
		};

		ahci@fd0c0000 {
			compatible = "ceva,ahci-1v84";
			status = "disabled";
			reg = <0x0 0xfd0c0000 0x0 0x2000>;
			interrupt-parent = <0x4>;
			interrupts = <0x0 0x85 0x4>;
			power-domains = <0xc 0x1c>;
			#stream-id-cells = <0x4>;
			clocks = <0x3 0x16>;
		};

		mmc@ff160000 {
			u-boot,dm-pre-reloc;
			compatible = "xlnx,zynqmp-8.9a", "arasan,sdhci-8.9a";
			status = "okay";
			interrupt-parent = <0x4>;
			interrupts = <0x0 0x30 0x4>;
			reg = <0x0 0xff160000 0x0 0x1000>;
			clock-names = "clk_xin", "clk_ahb";
			xlnx,device_id = <0x0>;
			#stream-id-cells = <0x1>;
			iommus = <0xd 0x870>;
			power-domains = <0xc 0x27>;
			clocks = <0x3 0x36 0x3 0x1f>;
			clock-frequency = <0xb2d0529>;
			xlnx,mio_bank = <0x0>;
			no-1-8-v;
			disable-wp;
		};

		mmc@ff170000 {
			u-boot,dm-pre-reloc;
			compatible = "xlnx,zynqmp-8.9a", "arasan,sdhci-8.9a";
			status = "okay";
			interrupt-parent = <0x4>;
			interrupts = <0x0 0x31 0x4>;
			reg = <0x0 0xff170000 0x0 0x1000>;
			clock-names = "clk_xin", "clk_ahb";
			xlnx,device_id = <0x1>;
			#stream-id-cells = <0x1>;
			iommus = <0xd 0x871>;
			power-domains = <0xc 0x28>;
			clocks = <0x3 0x37 0x3 0x1f>;
			clock-frequency = <0xb2d0529>;
			xlnx,mio_bank = <0x1>;
			bus-width = <0x4>;
			non-removable;
			disable-wp;
			cap-power-off-card;
			mmc-pwrseq = <0x17>;
			vqmmc-supply = <0x18>;
			#address-cells = <0x1>;
			#size-cells = <0x0>;

			wifi@2 {
				compatible = "ti,wl1831";
				reg = <0x2>;
				interrupt-parent = <0x10>;
				interrupts = <0x4c 0x1>;
			};
		};

		spi@ff040000 {
			compatible = "cdns,spi-r1p6";
			status = "okay";
			interrupt-parent = <0x4>;
			interrupts = <0x0 0x13 0x4>;
			reg = <0x0 0xff040000 0x0 0x1000>;
			clock-names = "ref_clk", "pclk";
			#address-cells = <0x1>;
			#size-cells = <0x0>;
			power-domains = <0xc 0x23>;
			clocks = <0x3 0x3a 0x3 0x1f>;
			is-decoded-cs = <0x0>;
			num-cs = <0x1>;
		};

		spi@ff050000 {
			compatible = "cdns,spi-r1p6";
			status = "okay";
			interrupt-parent = <0x4>;
			interrupts = <0x0 0x14 0x4>;
			reg = <0x0 0xff050000 0x0 0x1000>;
			clock-names = "ref_clk", "pclk";
			#address-cells = <0x1>;
			#size-cells = <0x0>;
			power-domains = <0xc 0x24>;
			clocks = <0x3 0x3b 0x3 0x1f>;
			is-decoded-cs = <0x0>;
			num-cs = <0x1>;
		};

		timer@ff110000 {
			compatible = "cdns,ttc";
			status = "disabled";
			interrupt-parent = <0x4>;
			interrupts = <0x0 0x24 0x4 0x0 0x25 0x4 0x0 0x26 0x4>;
			reg = <0x0 0xff110000 0x0 0x1000>;
			timer-width = <0x20>;
			power-domains = <0xc 0x18>;
			clocks = <0x3 0x1f>;
		};

		timer@ff120000 {
			compatible = "cdns,ttc";
			status = "disabled";
			interrupt-parent = <0x4>;
			interrupts = <0x0 0x27 0x4 0x0 0x28 0x4 0x0 0x29 0x4>;
			reg = <0x0 0xff120000 0x0 0x1000>;
			timer-width = <0x20>;
			power-domains = <0xc 0x19>;
			clocks = <0x3 0x1f>;
		};

		timer@ff130000 {
			compatible = "cdns,ttc";
			status = "disabled";
			interrupt-parent = <0x4>;
			interrupts = <0x0 0x2a 0x4 0x0 0x2b 0x4 0x0 0x2c 0x4>;
			reg = <0x0 0xff130000 0x0 0x1000>;
			timer-width = <0x20>;
			power-domains = <0xc 0x1a>;
			clocks = <0x3 0x1f>;
		};

		timer@ff140000 {
			compatible = "cdns,ttc";
			status = "disabled";
			interrupt-parent = <0x4>;
			interrupts = <0x0 0x2d 0x4 0x0 0x2e 0x4 0x0 0x2f 0x4>;
			reg = <0x0 0xff140000 0x0 0x1000>;
			timer-width = <0x20>;
			power-domains = <0xc 0x1b>;
			clocks = <0x3 0x1f>;
		};

		serial@ff000000 {
			u-boot,dm-pre-reloc;
			compatible = "cdns,uart-r1p12", "xlnx,xuartps";
			status = "okay";
			interrupt-parent = <0x4>;
			interrupts = <0x0 0x15 0x4>;
			reg = <0x0 0xff000000 0x0 0x1000>;
			clock-names = "uart_clk", "pclk";
			power-domains = <0xc 0x21>;
			clocks = <0x3 0x38 0x3 0x1f>;
			cts-override;
			device_type = "serial";
			port-number = <0x2>;

			bluetooth {
				compatible = "ti,wl1831-st";
				enable-gpios = <0x10 0x8 0x0>;
			};
		};

		serial@ff010000 {
			u-boot,dm-pre-reloc;
			compatible = "cdns,uart-r1p12", "xlnx,xuartps";
			status = "okay";
			interrupt-parent = <0x4>;
			interrupts = <0x0 0x16 0x4>;
			reg = <0x0 0xff010000 0x0 0x1000>;
			clock-names = "uart_clk", "pclk";
			power-domains = <0xc 0x22>;
			clocks = <0x3 0x39 0x3 0x1f>;
			cts-override;
			device_type = "serial";
			port-number = <0x0>;
		};

		usb0@ff9d0000 {
			#address-cells = <0x2>;
			#size-cells = <0x2>;
			status = "okay";
			compatible = "xlnx,zynqmp-dwc3";
			reg = <0x0 0xff9d0000 0x0 0x100>;
			clock-names = "bus_clk", "ref_clk";
			power-domains = <0xc 0x16>;
			ranges;
			nvmem-cells = <0x15>;
			nvmem-cell-names = "soc_revision";
			clocks = <0x3 0x20 0x3 0x22>;
			xlnx,tz-nonsecure = <0x1>;
			xlnx,usb-polarity = <0x0>;
			xlnx,usb-reset-mode = <0x0>;

			dwc3@fe200000 {
				compatible = "snps,dwc3";
				status = "okay";
				reg = <0x0 0xfe200000 0x0 0x40000>;
				interrupt-parent = <0x4>;
				interrupt-names = "dwc_usb3", "otg", "hiber";
				interrupts = <0x0 0x41 0x4 0x0 0x45 0x4 0x0 0x4b 0x4>;
				#stream-id-cells = <0x1>;
				iommus = <0xd 0x860>;
				snps,quirk-frame-length-adjustment = <0x20>;
				snps,refclk_fladj;
				snps,enable_guctl1_resume_quirk;
				snps,enable_guctl1_ipd_quirk;
				snps,xhci-stream-quirk;
				dr_mode = "peripheral";
				phy-names = "usb3-phy";
				phys = <0x19 0x4 0x0 0x0 0x18cba80>;
				maximum-speed = "super-speed";
			};
		};

		usb1@ff9e0000 {
			#address-cells = <0x2>;
			#size-cells = <0x2>;
			status = "okay";
			compatible = "xlnx,zynqmp-dwc3";
			reg = <0x0 0xff9e0000 0x0 0x100>;
			clock-names = "bus_clk", "ref_clk";
			power-domains = <0xc 0x17>;
			ranges;
			nvmem-cells = <0x15>;
			nvmem-cell-names = "soc_revision";
			clocks = <0x3 0x21 0x3 0x22>;
			xlnx,tz-nonsecure = <0x0>;
			xlnx,usb-polarity = <0x0>;
			xlnx,usb-reset-mode = <0x0>;

			dwc3@fe300000 {
				compatible = "snps,dwc3";
				status = "okay";
				reg = <0x0 0xfe300000 0x0 0x40000>;
				interrupt-parent = <0x4>;
				interrupt-names = "dwc_usb3", "otg", "hiber";
				interrupts = <0x0 0x46 0x4 0x0 0x4a 0x4 0x0 0x4c 0x4>;
				#stream-id-cells = <0x1>;
				iommus = <0xd 0x861>;
				snps,quirk-frame-length-adjustment = <0x20>;
				snps,refclk_fladj;
				snps,enable_guctl1_resume_quirk;
				snps,enable_guctl1_ipd_quirk;
				snps,xhci-stream-quirk;
				dr_mode = "host";
				phy-names = "usb3-phy";
				phys = <0x1a 0x4 0x1 0x0 0x18cba80>;
				maximum-speed = "super-speed";
			};
		};

		watchdog@fd4d0000 {
			compatible = "cdns,wdt-r1p2";
			status = "disabled";
			interrupt-parent = <0x4>;
			interrupts = <0x0 0x71 0x1>;
			reg = <0x0 0xfd4d0000 0x0 0x1000>;
			timeout-sec = <0x3c>;
			reset-on-timeout;
			clocks = <0x3 0x4b>;
		};

		watchdog@ff150000 {
			compatible = "cdns,wdt-r1p2";
			status = "disabled";
			interrupt-parent = <0x4>;
			interrupts = <0x0 0x34 0x1>;
			reg = <0x0 0xff150000 0x0 0x1000>;
			timeout-sec = <0xa>;
			clocks = <0x3 0x70>;
		};

		ams@ffa50000 {
			compatible = "xlnx,zynqmp-ams";
			status = "okay";
			interrupt-parent = <0x4>;
			interrupts = <0x0 0x38 0x4>;
			interrupt-names = "ams-irq";
			reg = <0x0 0xffa50000 0x0 0x800>;
			reg-names = "ams-base";
			#address-cells = <0x2>;
			#size-cells = <0x2>;
			#io-channel-cells = <0x1>;
			ranges;
			clocks = <0x3 0x46>;
			phandle = <0x2d>;

			ams_ps@ffa50800 {
				compatible = "xlnx,zynqmp-ams-ps";
				status = "okay";
				reg = <0x0 0xffa50800 0x0 0x400>;
			};

			ams_pl@ffa50c00 {
				compatible = "xlnx,zynqmp-ams-pl";
				status = "okay";
				reg = <0x0 0xffa50c00 0x0 0x400>;
			};
		};

		dma@fd4c0000 {
			compatible = "xlnx,dpdma";
			status = "okay";
			reg = <0x0 0xfd4c0000 0x0 0x1000>;
			interrupts = <0x0 0x7a 0x4>;
			interrupt-parent = <0x4>;
			clock-names = "axi_clk";
			power-domains = <0xc 0x29>;
			dma-channels = <0x6>;
			#dma-cells = <0x1>;
			clocks = <0x3 0x14>;
			phandle = <0x1e>;

			dma-video0channel {
				compatible = "xlnx,video0";
			};

			dma-video1channel {
				compatible = "xlnx,video1";
			};

			dma-video2channel {
				compatible = "xlnx,video2";
			};

			dma-graphicschannel {
				compatible = "xlnx,graphics";
			};

			dma-audio0channel {
				compatible = "xlnx,audio0";
			};

			dma-audio1channel {
				compatible = "xlnx,audio1";
			};
		};

		zynqmp-display@fd4a0000 {
			compatible = "xlnx,zynqmp-dpsub-1.7";
			status = "okay";
			reg = <0x0 0xfd4a0000 0x0 0x1000 0x0 0xfd4aa000 0x0 0x1000 0x0 0xfd4ab000 0x0 0x1000 0x0 0xfd4ac000 0x0 0x1000>;
			reg-names = "dp", "blend", "av_buf", "aud";
			interrupts = <0x0 0x77 0x4>;
			interrupt-parent = <0x4>;
			clock-names = "dp_apb_clk", "dp_aud_clk", "dp_vtc_pixel_clk_in";
			power-domains = <0xc 0x29>;
			clocks = <0x1b 0x3 0x11 0x3 0x10>;
			phy-names = "dp-phy0", "dp-phy1";
			phys = <0x1c 0x6 0x0 0x1 0x19bfcc0 0x1d 0x6 0x1 0x1 0x19bfcc0>;
			xlnx,max-lanes = <0x2>;

			vid-layer {
				dma-names = "vid0", "vid1", "vid2";
				dmas = <0x1e 0x0 0x1e 0x1 0x1e 0x2>;
			};

			gfx-layer {
				dma-names = "gfx0";
				dmas = <0x1e 0x3>;
			};

			i2c-bus {
			};

			zynqmp_dp_snd_codec0 {
				compatible = "xlnx,dp-snd-codec";
				clock-names = "aud_clk";
				clocks = <0x3 0x11>;
				status = "okay";
				phandle = <0x21>;
			};

			zynqmp_dp_snd_pcm0 {
				compatible = "xlnx,dp-snd-pcm";
				dmas = <0x1e 0x4>;
				dma-names = "tx";
				status = "okay";
				phandle = <0x1f>;
			};

			zynqmp_dp_snd_pcm1 {
				compatible = "xlnx,dp-snd-pcm";
				dmas = <0x1e 0x5>;
				dma-names = "tx";
				status = "okay";
				phandle = <0x20>;
			};

			zynqmp_dp_snd_card {
				compatible = "xlnx,dp-snd-card";
				xlnx,dp-snd-pcm = <0x1f 0x20>;
				xlnx,dp-snd-codec = <0x21>;
				status = "okay";
			};
		};
	};

	fclk0 {
		status = "okay";
		compatible = "xlnx,fclk";
		clocks = <0x3 0x47>;
	};

	fclk1 {
		status = "okay";
		compatible = "xlnx,fclk";
		clocks = <0x3 0x48>;
	};

	fclk2 {
		status = "okay";
		compatible = "xlnx,fclk";
		clocks = <0x3 0x49>;
	};

	fclk3 {
		status = "okay";
		compatible = "xlnx,fclk";
		clocks = <0x3 0x4a>;
	};

	pss_ref_clk {
		u-boot,dm-pre-reloc;
		compatible = "fixed-clock";
		#clock-cells = <0x0>;
		clock-frequency = <0x1fca034>;
		phandle = <0x6>;
	};

	video_clk {
		u-boot,dm-pre-reloc;
		compatible = "fixed-clock";
		#clock-cells = <0x0>;
		clock-frequency = <0x19bfcc0>;
		phandle = <0x7>;
	};

	pss_alt_ref_clk {
		u-boot,dm-pre-reloc;
		compatible = "fixed-clock";
		#clock-cells = <0x0>;
		clock-frequency = <0x0>;
		phandle = <0x8>;
	};

	gt_crx_ref_clk {
		u-boot,dm-pre-reloc;
		compatible = "fixed-clock";
		#clock-cells = <0x0>;
		clock-frequency = <0x66ff300>;
		phandle = <0xa>;
	};

	aux_ref_clk {
		u-boot,dm-pre-reloc;
		compatible = "fixed-clock";
		#clock-cells = <0x0>;
		clock-frequency = <0x19bfcc0>;
		phandle = <0x9>;
	};

	dp_aclk {
		compatible = "fixed-clock";
		#clock-cells = <0x0>;
		clock-frequency = <0x5f5e100>;
		clock-accuracy = <0x64>;
		phandle = <0x1b>;
	};

	amba_pl@0 {
		#address-cells = <0x2>;
		#size-cells = <0x2>;
		compatible = "simple-bus";
		ranges;

		audio_formatter@80050000 {
			clock-names = "s_axi_lite_aclk", "m_axis_mm2s_aclk", "aud_mclk", "s_axis_s2mm_aclk";
			clocks = <0x3 0x47 0x3 0x47 0x22 0x3 0x47>;
			compatible = "xlnx,audio-formatter-1.0", "xlnx,audio-formatter-1.0";
			interrupt-names = "irq_mm2s", "irq_s2mm";
			interrupt-parent = <0x4>;
			interrupts = <0x0 0x5e 0x4 0x0 0x5d 0x4>;
			reg = <0x0 0x80050000 0x0 0x1000>;
			xlnx,include-mm2s = <0x1>;
			xlnx,include-s2mm = <0x1>;
			xlnx,max-num-channels-mm2s = <0x2>;
			xlnx,max-num-channels-s2mm = <0x2>;
			xlnx,mm2s-addr-width = <0x40>;
			xlnx,mm2s-async-clock = <0x1>;
			xlnx,mm2s-dataformat = <0x3>;
			xlnx,packing-mode-mm2s = <0x0>;
			xlnx,packing-mode-s2mm = <0x0>;
			xlnx,rx = <0x23>;
			xlnx,s2mm-addr-width = <0x40>;
			xlnx,s2mm-async-clock = <0x1>;
			xlnx,s2mm-dataformat = <0x1>;
			xlnx,tx = <0x24>;
			phandle = <0x25>;
		};

		misc_clk_0 {
			#clock-cells = <0x0>;
			clock-frequency = <0x1193fef>;
			compatible = "fixed-clock";
			phandle = <0x22>;
		};

		serial@80060000 {
			clock-frequency = <0x5f5e09d>;
			clock-names = "s_axi_aclk";
			clocks = <0x3 0x47>;
			compatible = "xlnx,xps-uart16550-2.00.a", "ns16550a";
			current-speed = <0x1c200>;
			device_type = "serial";
			interrupt-names = "ip2intc_irpt";
			interrupt-parent = <0x4>;
			interrupts = <0x0 0x59 0x4>;
			port-number = <0x1>;
			reg = <0x0 0x80060000 0x0 0x10000>;
			reg-offset = <0x1000>;
			reg-shift = <0x2>;
			xlnx,external-xin-clk-hz = <0x17d7840>;
			xlnx,external-xin-clk-hz-d = <0x19>;
			xlnx,has-external-rclk = <0x0>;
			xlnx,has-external-xin = <0x0>;
			xlnx,is-a-16550 = <0x1>;
			xlnx,s-axi-aclk-freq-hz-d = "99.999901";
			xlnx,use-modem-ports = <0x1>;
			xlnx,use-user-ports = <0x1>;
		};

		i2s_receiver@80030000 {
			aud_mclk = <0x1193fef>;
			clock-names = "s_axi_ctrl_aclk", "aud_mclk", "m_axis_aud_aclk";
			clocks = <0x3 0x47 0x22 0x3 0x47>;
			compatible = "xlnx,i2s-receiver-1.0", "xlnx,i2s-receiver-1.0";
			interrupt-names = "irq";
			interrupt-parent = <0x4>;
			interrupts = <0x0 0x5c 0x4>;
			reg = <0x0 0x80030000 0x0 0x10000>;
			xlnx,depth = <0x200>;
			xlnx,dwidth = <0x18>;
			xlnx,num-channels = <0x1>;
			xlnx,snd-pcm = <0x25>;
			phandle = <0x23>;
		};

		i2s_transmitter@80040000 {
			aud_mclk = <0x1193fef>;
			clock-names = "s_axi_ctrl_aclk", "aud_mclk", "s_axis_aud_aclk";
			clocks = <0x3 0x47 0x22 0x3 0x47>;
			compatible = "xlnx,i2s-transmitter-1.0", "xlnx,i2s-transmitter-1.0";
			interrupt-names = "irq";
			interrupt-parent = <0x4>;
			interrupts = <0x0 0x5f 0x4>;
			reg = <0x0 0x80040000 0x0 0x10000>;
			xlnx,depth = <0x80>;
			xlnx,dwidth = <0x18>;
			xlnx,num-channels = <0x1>;
			xlnx,snd-pcm = <0x25>;
			phandle = <0x24>;
		};

		mipi_csi2_rx_subsystem@80000000 {
			clock-names = "lite_aclk", "dphy_clk_200M", "video_aclk";
			clocks = <0x26 0x26 0x26>;
			compatible = "xlnx,mipi-csi2-rx-subsystem-4.0";
			xlnx,en-active-lanes;
			interrupt-names = "csirxss_csi_irq";
			interrupt-parent = <0x4>;
			interrupts = <0x0 0x5a 0x4>;
			reg = <0x0 0x80000000 0x0 0x20000>;
			xlnx,axis-tdata-width = <0x10>;
			xlnx,csi-pxl-format = "YUV422_8bit";
			xlnx,max-lanes = <0x4>;
			xlnx,ppc = <0x1>;
			xlnx,vc = <0x4>;
			xlnx,vfb;

			ports {
				#address-cells = <0x1>;
				#size-cells = <0x0>;

				port@0 {
					reg = <0x0>;
					xlnx,cfa-pattern = "rggb";
					xlnx,video-format = <0x0>;
					xlnx,video-width = <0x8>;

					endpoint {
						remote-endpoint = <0x27>;
						phandle = <0x29>;
					};
				};

				port@1 {
					reg = <0x1>;
					xlnx,cfa-pattern = "rggb";
					xlnx,video-format = <0x0>;
					xlnx,video-width = <0x8>;

					endpoint {
//						data-lanes = <0x1 0x2>;
//						remote-endpoint = <0x28>;
						data-lanes = <1 2 3 4>;
						remote-endpoint = <&max9286_out>;
						phandle = <0x12>;
					};
				};
			};
		};

		misc_clk_1 {
			#clock-cells = <0x0>;
			clock-frequency = <0xbebc200>;
			compatible = "fixed-clock";
			phandle = <0x26>;
		};

		PERIPHERAL@ff380000 {
			compatible = "xlnx,PERIPHERAL-1.0";
			reg = <0x0 0xff380000 0x0 0x80000>;
		};

		PERIPHERAL@ff990000 {
			compatible = "xlnx,PERIPHERAL-1.0";
			reg = <0x0 0xff990000 0x0 0x10000>;
		};

		v_frmbuf_wr@80020000 {
			#dma-cells = <0x1>;
			clock-names = "ap_clk";
			clocks = <0x26>;
			compatible = "xlnx,v-frmbuf-wr-2.1", "xlnx,axi-frmbuf-wr-v2.1";
			interrupt-names = "interrupt";
			interrupt-parent = <0x4>;
			interrupts = <0x0 0x5b 0x4>;
			reg = <0x0 0x80020000 0x0 0x10000>;
			reset-gpios = <0x10 0x54 0x1>;
			xlnx,dma-addr-width = <0x20>;
			xlnx,max-height = <0x870>;
			xlnx,max-width = <0xf00>;
			xlnx,pixels-per-clock = <0x1>;
			xlnx,vid-formats = "rgb888", "bgr888", "xbgr8888", "xbgr8888", "uyvy", "y8", "vuy888", "xvuy8888", "yuyv", "nv12", "nv16";
			phandle = <0x2b>;
		};

		v_proc_ss@80080000 {
			clock-names = "aclk_axis", "aclk_ctrl";
			clocks = <0x26 0x26>;
			compatible = "xlnx,v-proc-ss-2.0", "xlnx,v-vpss-scaler", "xlnx,vpss-scaler";
			reg = <0x0 0x80080000 0x0 0x40000>;
			reset-gpios = <0x10 0x55 0x1>;
			xlnx,max-height = <0x870>;
			xlnx,max-width = <0xf00>;
			xlnx,num-hori-taps = <0x8>;
			xlnx,num-vert-taps = <0x8>;
			xlnx,pix-per-clk = <0x1>;

			ports {
				#address-cells = <0x1>;
				#size-cells = <0x0>;

				port@0 {
					reg = <0x0>;
					xlnx,video-format = <0x0>;
					xlnx,video-width = <0x8>;

					endpoint {
						remote-endpoint = <0x29>;
						phandle = <0x27>;
					};
				};

				port@1 {
					reg = <0x1>;
					xlnx,video-format = <0x0>;
					xlnx,video-width = <0x8>;

					endpoint {
						remote-endpoint = <0x2a>;
						phandle = <0x2c>;
					};
				};
			};
		};

		vcap_csi {
			compatible = "xlnx,video";
			dma-names = "port0";
			dmas = <0x2b 0x0>;

			ports {
				#address-cells = <0x1>;
				#size-cells = <0x0>;

				port@0 {
					direction = "input";
					reg = <0x0>;

					endpoint {
						remote-endpoint = <0x2c>;
						phandle = <0x2a>;
					};
				};
			};
		};
	};

	gpio-keys {
		compatible = "gpio-keys";
		#address-cells = <0x1>;
		#size-cells = <0x0>;
		autorepeat;

		sw4 {
			label = "sw4";
			gpios = <0x10 0x17 0x1>;
			linux,code = <0x74>;
			gpio-key,wakeup;
			autorepeat;
		};
	};

	iio-hwmon {
		compatible = "iio-hwmon";
		io-channels = <0x2d 0x0 0x2d 0x1 0x2d 0x2 0x2d 0x3 0x2d 0x4 0x2d 0x5 0x2d 0x6 0x2d 0x7 0x2d 0x8 0x2d 0x9 0x2d 0xa 0x2d 0xb 0x2d 0xc>;
	};

	leds {
		compatible = "gpio-leds";

		ds2 {
			label = "ds2";
			gpios = <0x10 0x14 0x0>;
			linux,default-trigger = "heartbeat";
		};

		ds3 {
			label = "ds3";
			gpios = <0x10 0x13 0x0>;
			linux,default-trigger = "phy0tx";
			default-state = "off";
		};

		ds4 {
			label = "ds4";
			gpios = <0x10 0x12 0x0>;
			linux,default-trigger = "phy0rx";
			default-state = "off";
		};

		ds5 {
			label = "ds5";
			gpios = <0x10 0x11 0x0>;
			linux,default-trigger = "bluetooth-power";
		};

		vbus_det {
			label = "vbus_det";
			gpios = <0x10 0x19 0x0>;
			default-state = "on";
		};
	};

	ltc2954 {
		compatible = "lltc,ltc2954", "lltc,ltc2952";
		status = "disabled";
		trigger-gpios = <0x10 0x1a 0x1>;
		watchdog-gpios = <0x10 0x23 0x0>;
		kill-gpios = <0x10 0x22 0x1>;
	};

	fixedregulator-mmcsdio {
		compatible = "regulator-fixed";
		regulator-name = "wmmcsdio_fixed";
		regulator-min-microvolt = <0x325aa0>;
		regulator-max-microvolt = <0x325aa0>;
		regulator-always-on;
		regulator-boot-on;
		phandle = <0x18>;
	};

	sdio_pwrseq {
		compatible = "mmc-pwrseq-simple";
		reset-gpios = <0x10 0x7 0x1>;
		phandle = <0x17>;
	};

	chosen {
		bootargs = "earlycon console=ttyPS0,115200 clk_ignore_unused root=/dev/mmcblk0p2 rw rootwait";
		stdout-path = "serial0:115200n8";
	};

	aliases {
		i2c0 = "/amba/i2c@ff030000";
		serial0 = "/amba/serial@ff010000";
		serial1 = "/amba/serial@ff000000";
		serial2 = "/amba_pl@0/serial@80060000";
		spi0 = "/amba/spi@ff040000";
		spi1 = "/amba/spi@ff050000";
	};

	memory {
		device_type = "memory";
		reg = <0x0 0x0 0x0 0x7ff00000>;
	};

	mipi_clk {
		compatible = "fixed-clock";
		#clock-cells = <0x0>;
		clock-frequency = <0x16e3600>;
		phandle = <0x11>;
	};

	reserved-memory {
		#address-cells = <0x2>;
		#size-cells = <0x2>;
		ranges;

		rproc@3ed400000 {
			no-map;
			compatible = "shared-dma-pool";
			reg = <0x0 0x3ed40000 0x0 0x100000>;
			phandle = <0x2f>;
		};

		rproc@3ed000000 {
			no-map;
			reg = <0x0 0x3ed00000 0x0 0x40000>;
			phandle = <0x2e>;
		};
	};

	zynqmp-rpu {
		compatible = "xlnx,zynqmp-r5-remoteproc-1.0";
		#address-cells = <0x2>;
		#size-cells = <0x2>;
		ranges;
		core_conf = "split";

		r5@0 {
			#address-cells = <0x2>;
			#size-cells = <0x2>;
			ranges;
			memory-region = <0x2e 0x2f>;
			pnode-id = <0x7>;
			mboxes = <0x30 0x0 0x30 0x1>;
			mbox-names = "tx", "rx";

			tcm_0@0 {
				reg = <0x0 0xffe00000 0x0 0x10000>;
				pnode-id = <0xf>;
			};

			tcm_0@1 {
				reg = <0x0 0xffe20000 0x0 0x10000>;
				pnode-id = <0x10>;
			};
		};
	};

	zynqmp_ipi1 {
		compatible = "xlnx,zynqmp-ipi-mailbox";
		interrupt-parent = <0x4>;
		interrupts = <0x0 0x1d 0x4>;
		xlnx,ipi-id = <0x7>;
		#address-cells = <0x1>;
		#size-cells = <0x1>;
		ranges;

		mailbox@ff90000 {
			reg = <0xff990600 0x20 0xff990620 0x20 0xff9900c0 0x20 0xff9900e0 0x20>;
			reg-names = "local_request_region", "local_response_region", "remote_request_region", "remote_response_region";
			#mbox-cells = <0x1>;
			xlnx,ipi-id = <0x1>;
			phandle = <0x30>;
		};
	};
};
